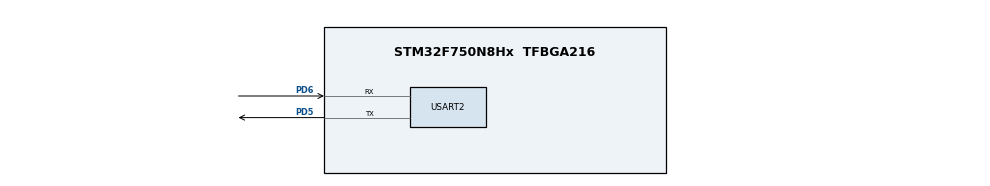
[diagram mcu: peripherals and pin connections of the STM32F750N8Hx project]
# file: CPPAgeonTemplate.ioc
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CORTEX_M7.default_mode_Activation=1
FREERTOS.Tasks01=defaultTask,24,128,StartDefaultTask,Default,NULL,Dynamic,NULL,NULL
Mcu.Family=STM32F7
Mcu.Name=STM32F750N8Hx
Mcu.Package=TFBGA216
Mcu.UserConstants=TEST_CONST,"My Const"
NVIC.PriorityGroup=NVIC_PRIORITYGROUP_4
NVIC.TIM1_UP_TIM10_IRQn=true\:15\:0\:false\:false\:true\:false\:false\:true\:true
NVIC.TimeBase=TIM1_UP_TIM10_IRQn
NVIC.TimeBaseIP=TIM1
PD5.Mode=Asynchronous
PD5.Signal=USART2_TX
PD6.Mode=Asynchronous
PD6.Signal=USART2_RX
ProjectManager.HeapSize=0x200
ProjectManager.StackSize=0x400
ProjectManager.TargetToolchain=CMake
RCC.HSE_VALUE=25000000
RCC.HSI_VALUE=16000000
RCC.LSE_VALUE=32768
RCC.USBFreq_Value=96000000
RCC.VCOOutputFreq_Value=192000000
STMicroelectronics.X-CUBE-TOUCHGFX.4.24.0.ApplicationCcGraphicsJjApplication=TouchGFXOoGenerator
STMicroelectronics.X-CUBE-TOUCHGFX.4.24.0.tgfx_buffering_strategy=Single
STMicroelectronics.X-CUBE-TOUCHGFX.4.24.0.tgfx_custom_height=480
STMicroelectronics.X-CUBE-TOUCHGFX.4.24.0.tgfx_custom_width=800
STMicroelectronics.X-CUBE-TOUCHGFX.4.24.0.tgfx_hardware_accelerator=dma_2d
STMicroelectronics.X-CUBE-TOUCHGFX.4.24.0_IsPackSelfContextualization=true
USART2.VirtualMode-Asynchronous=VM_ASYNC
VP_CRC_VS_CRC.Mode=CRC_Activate
VP_DMA2D_VS_DMA2D.Mode=DMA2D_Activate
VP_FREERTOS_VS_CMSIS_V2.Mode=CMSIS_V2
VP_LIBJPEG_VS_JPEGLIB.Mode=Enabled
VP_STMicroelectronics.X-CUBE-TOUCHGFX_VS_GraphicsJjApplication_4.24.0.Mode=GraphicsJjApplication
VP_SYS_VS_tim1.Mode=TIM1
board=custom

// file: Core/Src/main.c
/* USER CODE BEGIN Header */
/**
  ******************************************************************************
  * @file           : main.c
  * @brief          : Main program body
  ******************************************************************************
  * @attention
  *
  * Copyright (c) 2024 STMicroelectronics.
  * All rights reserved.
  *
  * This software is licensed under terms that can be found in the LICENSE file
  * in the root directory of this software component.
  * If no LICENSE file comes with this software, it is provided AS-IS.
  *
  ******************************************************************************
  */
/* USER CODE END Header */
#include "main.h"
#include "cmsis_os.h"
#include "libjpeg.h"
#include "app_touchgfx.h"

CRC_HandleTypeDef hcrc;

DMA2D_HandleTypeDef hdma2d;

UART_HandleTypeDef huart2;

/* Definitions for defaultTask */
osThreadId_t defaultTaskHandle;
const osThreadAttr_t defaultTask_attributes = {
  .name = "defaultTask",
  .stack_size = 128 * 4,
  .priority = (osPriority_t) osPriorityNormal,
};

void SystemClock_Config(void);
static void MPU_Config(void);
static void MX_GPIO_Init(void);
static void MX_CRC_Init(void);
static void MX_DMA2D_Init(void);
static void MX_USART2_UART_Init(void);
void StartDefaultTask(void *argument);

int main(void)
{

  /* MPU Configuration--------------------------------------------------------*/
  MPU_Config();

  /* MCU Configuration--------------------------------------------------------*/

  /* Reset of all peripherals, Initializes the Flash interface and the Systick. */
  HAL_Init();

  /* USER CODE BEGIN Init */
  uint8_t buffer[] = "Hello World\n";

  /* USER CODE END Init */

  /* Configure the system clock */
  SystemClock_Config();

  /* Initialize all configured peripherals */
  MX_GPIO_Init();
  MX_CRC_Init();
  MX_DMA2D_Init();
  MX_LIBJPEG_Init();
  MX_USART2_UART_Init();
  MX_TouchGFX_Init();
  /* Call PreOsInit function */
  MX_TouchGFX_PreOSInit();

  /* Init scheduler */
  osKernelInitialize();

  /* USER CODE BEGIN RTOS_QUEUES */
  /* add queues, ... */
  // TODO: Add queues here or inside app_main?
  /* USER CODE END RTOS_QUEUES */

  /* Create the thread(s) */
  /* creation of defaultTask */
  defaultTaskHandle = osThreadNew(StartDefaultTask, NULL, &defaultTask_attributes);

  /* USER CODE BEGIN RTOS_THREADS */
  /* add threads, ... */
  // TODO: Add main thread here or inside app_main?
  app_main();
  /* USER CODE END RTOS_THREADS */

  /* Start scheduler */
  osKernelStart();

  /* We should never get here as control is now taken by the scheduler */

  /* Infinite loop */
  while (1)
  {

  }
}

void SystemClock_Config(void)
{
  RCC_OscInitTypeDef RCC_OscInitStruct = {0};
  RCC_ClkInitTypeDef RCC_ClkInitStruct = {0};

  /** Configure the main internal regulator output voltage
  */
  __HAL_RCC_PWR_CLK_ENABLE();
  __HAL_PWR_VOLTAGESCALING_CONFIG(PWR_REGULATOR_VOLTAGE_SCALE3);

  /** Initializes the RCC Oscillators according to the specified parameters
  * in the RCC_OscInitTypeDef structure.
  */
  RCC_OscInitStruct.OscillatorType = RCC_OSCILLATORTYPE_HSI;
  RCC_OscInitStruct.HSIState = RCC_HSI_ON;
  RCC_OscInitStruct.HSICalibrationValue = RCC_HSICALIBRATION_DEFAULT;
  RCC_OscInitStruct.PLL.PLLState = RCC_PLL_NONE;
  if (HAL_RCC_OscConfig(&RCC_OscInitStruct) != HAL_OK)
  {
    Error_Handler();
  }

  /** Initializes the CPU, AHB and APB buses clocks
  */
  RCC_ClkInitStruct.ClockType = RCC_CLOCKTYPE_HCLK|RCC_CLOCKTYPE_SYSCLK
                              |RCC_CLOCKTYPE_PCLK1|RCC_CLOCKTYPE_PCLK2;
  RCC_ClkInitStruct.SYSCLKSource = RCC_SYSCLKSOURCE_HSI;
  RCC_ClkInitStruct.AHBCLKDivider = RCC_SYSCLK_DIV1;
  RCC_ClkInitStruct.APB1CLKDivider = RCC_HCLK_DIV1;
  RCC_ClkInitStruct.APB2CLKDivider = RCC_HCLK_DIV1;

  if (HAL_RCC_ClockConfig(&RCC_ClkInitStruct, FLASH_LATENCY_0) != HAL_OK)
  {
    Error_Handler();
  }
}

static void MX_CRC_Init(void)
{

  hcrc.Instance = CRC;
  hcrc.Init.DefaultPolynomialUse = DEFAULT_POLYNOMIAL_ENABLE;
  hcrc.Init.DefaultInitValueUse = DEFAULT_INIT_VALUE_ENABLE;
  hcrc.Init.InputDataInversionMode = CRC_INPUTDATA_INVERSION_NONE;
  hcrc.Init.OutputDataInversionMode = CRC_OUTPUTDATA_INVERSION_DISABLE;
  hcrc.InputDataFormat = CRC_INPUTDATA_FORMAT_BYTES;
  if (HAL_CRC_Init(&hcrc) != HAL_OK)
  {
    Error_Handler();
  }

}

static void MX_DMA2D_Init(void)
{

  hdma2d.Instance = DMA2D;
  hdma2d.Init.Mode = DMA2D_M2M;
  hdma2d.Init.ColorMode = DMA2D_OUTPUT_ARGB8888;
  hdma2d.Init.OutputOffset = 0;
  hdma2d.LayerCfg[1].InputOffset = 0;
  hdma2d.LayerCfg[1].InputColorMode = DMA2D_INPUT_ARGB8888;
  hdma2d.LayerCfg[1].AlphaMode = DMA2D_NO_MODIF_ALPHA;
  hdma2d.LayerCfg[1].InputAlpha = 0;
  if (HAL_DMA2D_Init(&hdma2d) != HAL_OK)
  {
    Error_Handler();
  }
  if (HAL_DMA2D_ConfigLayer(&hdma2d, 1) != HAL_OK)
  {
    Error_Handler();
  }

}

static void MX_USART2_UART_Init(void)
{

  huart2.Instance = USART2;
  huart2.Init.BaudRate = 115200;
  huart2.Init.WordLength = UART_WORDLENGTH_8B;
  huart2.Init.StopBits = UART_STOPBITS_1;
  huart2.Init.Parity = UART_PARITY_NONE;
  huart2.Init.Mode = UART_MODE_TX_RX;
  huart2.Init.HwFlowCtl = UART_HWCONTROL_NONE;
  huart2.Init.OverSampling = UART_OVERSAMPLING_16;
  huart2.Init.OneBitSampling = UART_ONE_BIT_SAMPLE_DISABLE;
  huart2.AdvancedInit.AdvFeatureInit = UART_ADVFEATURE_NO_INIT;
  if (HAL_UART_Init(&huart2) != HAL_OK)
  {
    Error_Handler();
  }

}

static void MX_GPIO_Init(void)
{

  /* GPIO Ports Clock Enable */
  __HAL_RCC_GPIOD_CLK_ENABLE();

}

void StartDefaultTask(void *argument)
{
  for(;;)
  {
    osDelay(1);
  }
}

 /* MPU Configuration */

void MPU_Config(void)
{
  MPU_Region_InitTypeDef MPU_InitStruct = {0};

  /* Disables the MPU */
  HAL_MPU_Disable();

  /** Initializes and configures the Region and the memory to be protected
  */
  MPU_InitStruct.Enable = MPU_REGION_ENABLE;
  MPU_InitStruct.Number = MPU_REGION_NUMBER0;
  MPU_InitStruct.BaseAddress = 0x0;
  MPU_InitStruct.Size = MPU_REGION_SIZE_4GB;
  MPU_InitStruct.SubRegionDisable = 0x87;
  MPU_InitStruct.TypeExtField = MPU_TEX_LEVEL0;
  MPU_InitStruct.AccessPermission = MPU_REGION_NO_ACCESS;
  MPU_InitStruct.DisableExec = MPU_INSTRUCTION_ACCESS_DISABLE;
  MPU_InitStruct.IsShareable = MPU_ACCESS_SHAREABLE;
  MPU_InitStruct.IsCacheable = MPU_ACCESS_NOT_CACHEABLE;
  MPU_InitStruct.IsBufferable = MPU_ACCESS_NOT_BUFFERABLE;

  HAL_MPU_ConfigRegion(&MPU_InitStruct);
  /* Enables the MPU */
  HAL_MPU_Enable(MPU_PRIVILEGED_DEFAULT);

}

void HAL_TIM_PeriodElapsedCallback(TIM_HandleTypeDef *htim)
{
  if (htim->Instance == TIM1) {
    HAL_IncTick();
  }
}

void Error_Handler(void)
{
  __disable_irq();
  while (1)
  {
  }
}
